# RA2A1 register map
Vendor: Renesas Electronics Corporation; Series: RA2; File version: 1.1
CPU: other r1p0, little endian, MPU, no FPU, VTOR, 2 interrupt priority bits
Registers are 8-bit, read-write, reset 0x0 unless marked. A register's access mark holds for its fields unless they carry their own. Offsets are from the block's base; [hi:lo] are bit positions; {n}, {i} and the like mark numbered series; 'fields as' and 'values as' point back to an identical list.

## SRAM — SRAM Control
Base 0x40002000
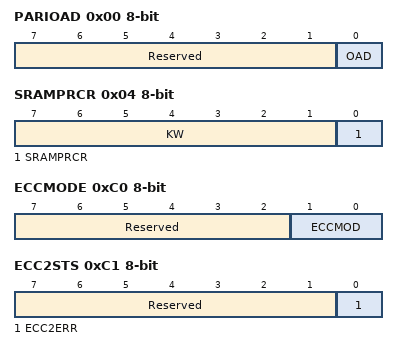
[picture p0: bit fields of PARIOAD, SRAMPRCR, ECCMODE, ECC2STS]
0x00 PARIOAD — SRAM Parity Error Operation After Detection Register
  [7:1] Reserved — These bits are read as 0000000. The write value should be 0000000.
  [0] OAD — Operation after Detection
    1=Reset; 0=Non maskable interrupt
0x04 SRAMPRCR — SRAM Protection Register
  [7:1] KW wo — Write Key Code
    120=Writing to the RAMPRCR bit is valid, when the KEY bits are written 1111000b; other=others (Writing to the RAMPRCR bit is invalid.)
  [0] SRAMPRCR — Register Write Control
    0=Writing to the protected register is disabled; 1=Writing to the protected register is enabled
0xC0 ECCMODE — ECC Operating Mode Control Register
  [7:2] Reserved — These bits are read as 000000. The write value should be 000000.
  [1:0] ECCMOD — ECC Operating Mode Select
    0=ECC is disabled; 1=Setting prohibited; 2=ECC is enabled without error checking; 3=ECC is enabled with error checking
0xC1 ECC2STS — ECC 2-Bit Error Status Register
  [7:1] Reserved — These bits are read as 0000000. The write value should be 0000000.
  [0] ECC2ERR write-0-clears read-modifies — ECC 2-Bit Error Status
    0=A 2-bit ECC error has not occurred; 1=A 2-bit ECC error has occurred
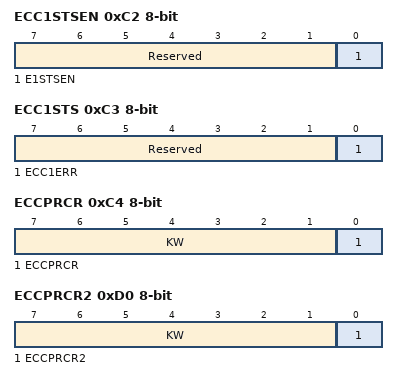
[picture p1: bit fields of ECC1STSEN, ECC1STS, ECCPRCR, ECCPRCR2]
0xC2 ECC1STSEN — ECC 1-Bit Error Information Update Enable Register
  [7:1] Reserved — These bits are read as 0000000. The write value should be 0000000.
  [0] E1STSEN — ECC 1-Bit Error Information Update Enable
    0=Disables updating of the 1-bit ECC error information; 1=Enables updating of the 1-bit ECC error information
0xC3 ECC1STS — ECC 1-Bit Error Status Register
  [7:1] Reserved — These bits are read as 0000000. The write value should be 0000000.
  [0] ECC1ERR write-0-clears read-modifies — ECC 1-Bit Error Status
    0=A 1-bit ECC error has not occurred; 1=A 1-bit ECC error has occurred
0xC4 ECCPRCR — ECC Protection Register
  [7:1] KW wo — Write Key Code
    120=Writing to the ECCPRCR bit is valid, when the KW bits are written 1111000b; other=others (Writing to the ECCPRCR bit is invalid.)
  [0] ECCPRCR — Register Write Control
    0=Writing to the protect register is disabled; 1=Writing to the protect register is enabled
0xD0 ECCPRCR2 — ECC Protection Register 2
  [7:1] KW wo — Write Key Code
    120=Writing to the ECCPRCR2 bit is valid, when the KEY bits are written 1111000b; other=others (Writing to the ECCPRCR2 bit is invalid.)
  [0] ECCPRCR2 — Register Write Control
    values as ECCPRCR.ECCPRCR
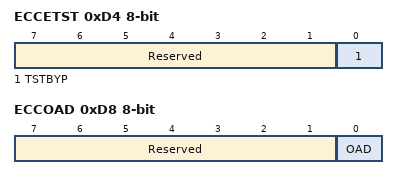
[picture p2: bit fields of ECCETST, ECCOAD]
0xD4 ECCETST — ECC Test Control Register
  [7:1] Reserved — These bits are read as 0000000. The write value should be 0000000.
  [0] TSTBYP — ECC Bypass Select
    0=ECC bypass is disabled; 1=ECC bypass is enabled
0xD8 ECCOAD — SRAM ECC Error Operation After Detection Register
  [7:1] Reserved — These bits are read as 0000000. The write value should be 0000000.
  [0] OAD — Operation after Detection
    0=Non maskable interrupt; 1=Internal reset

## BUS — BUS Control
Base 0x40003000
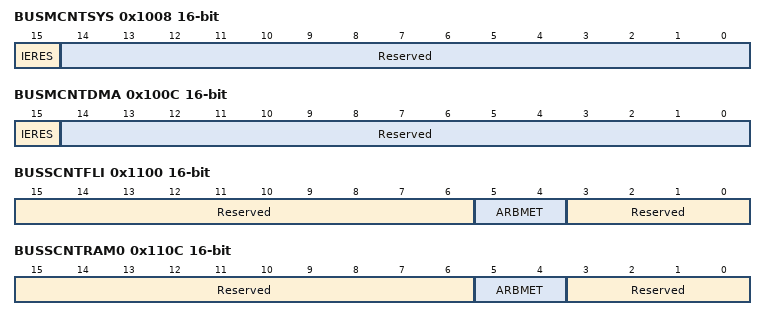
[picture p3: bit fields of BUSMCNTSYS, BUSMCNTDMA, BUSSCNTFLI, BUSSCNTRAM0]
0x1008 BUSMCNTSYS 16-bit — Master Bus Control Register SYS
  [15] IERES — Ignore Error Responses
    0=Bus error will be reported; 1=Bus error will not be reported
  [14:0] Reserved — These bits are read as 000000000000000. The write value should be 000000000000000.
0x100C BUSMCNTDMA 16-bit — Master Bus Control Register DMA
  fields as BUSMCNTSYS
0x1100 BUSSCNTFLI 16-bit — Slave Bus Control Register FLI
  [15:6] Reserved — These bits are read as 0000000000. The write value should be 0000000000.
  [5:4] ARBMET — Arbitration MethodSpecify the priority between groups
    0=fixed priority; 1=round-robin; other=others (Setting prohibited)
  [3:0] Reserved — These bits are read as 0000. The write value should be 0000.
0x110C BUSSCNTRAM0 16-bit — Slave Bus Control Register RAM0
  fields as BUSSCNTFLI
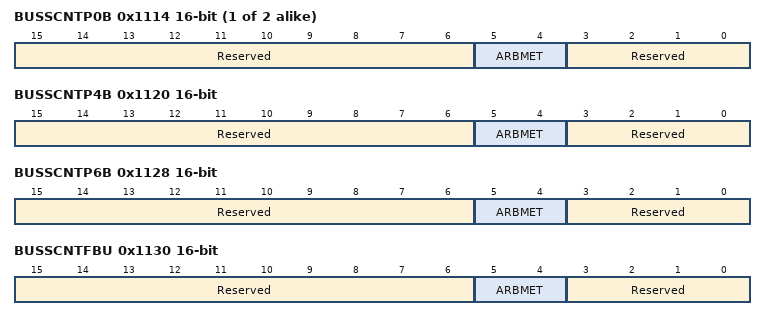
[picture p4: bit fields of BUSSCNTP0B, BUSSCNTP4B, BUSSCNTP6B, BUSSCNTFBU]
0x1114 BUSSCNT{x} (x=P0B,P2B; step 0x4) 16-bit — Slave Bus Control Register {x}
  fields as BUSSCNTFLI
0x1120 BUSSCNTP4B 16-bit — Slave Bus Control Register P4B
  fields as BUSSCNTFLI
0x1128 BUSSCNTP6B 16-bit — Slave Bus Control Register P6B
  fields as BUSSCNTFLI
0x1130 BUSSCNTFBU 16-bit — Slave Bus Control Register FBU
  fields as BUSSCNTFLI
{0x17F0+0x10*i} BUS{i}ERRADD (i=3..4) 32-bit ro reset not defined — Bus Error Address Register {i}
  [31:0] BERAD — Bus Error AddressWhen a bus error occurs, It stores an error address.
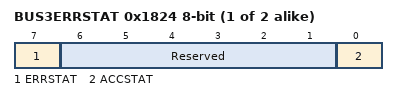
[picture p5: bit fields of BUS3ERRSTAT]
{0x17F4+0x10*i} BUS{i}ERRSTAT (i=3..4) ro (reset mask 0xFE) — Bus Error Status Register {i}
  [7] ERRSTAT — Bus Error StatusWhen bus error assert, error flag occurs.
    0=No bus error occurred; 1=Bus error occurred
  [6:1] Reserved — These bits are read as 000000.
  [0] ACCSTAT — Error access statusThe status at the time of the error
    0=Read access; 1=Write Access
